VERSION ""

NS_ :

BS_:

BU_:

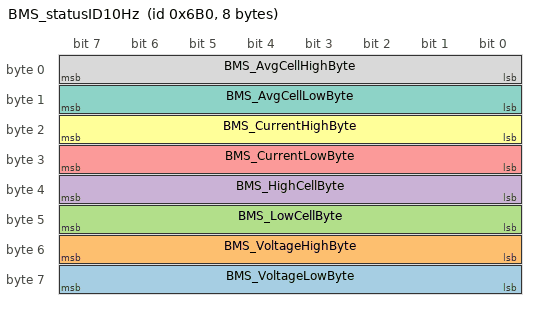
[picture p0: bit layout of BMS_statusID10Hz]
BO_ 1712 BMS_statusID10Hz: 8 Vector__XXX
 SG_ BMS_VoltageLowByte : 63|8@0+ (0.1,0) [0|25.5] "V" Vector__XXX
 SG_ BMS_VoltageHighByte : 55|8@0+ (0.1,0) [0|25.5] "V" Vector__XXX
 SG_ BMS_LowCellByte : 47|8@0+ (1,0) [0|255] "C" Vector__XXX
 SG_ BMS_HighCellByte : 39|8@0+ (1,0) [0|255] "C" Vector__XXX
 SG_ BMS_CurrentLowByte : 31|8@0+ (0.1,0) [0|25.5] "A" Vector__XXX
 SG_ BMS_CurrentHighByte : 23|8@0+ (0.1,0) [0|25.5] "A" Vector__XXX
 SG_ BMS_AvgCellLowByte : 15|8@0+ (0.001,0) [0|0.255] "V" Vector__XXX
 SG_ BMS_AvgCellHighByte : 7|8@0+ (0.001,0) [0|0.255] "V" Vector__XXX
